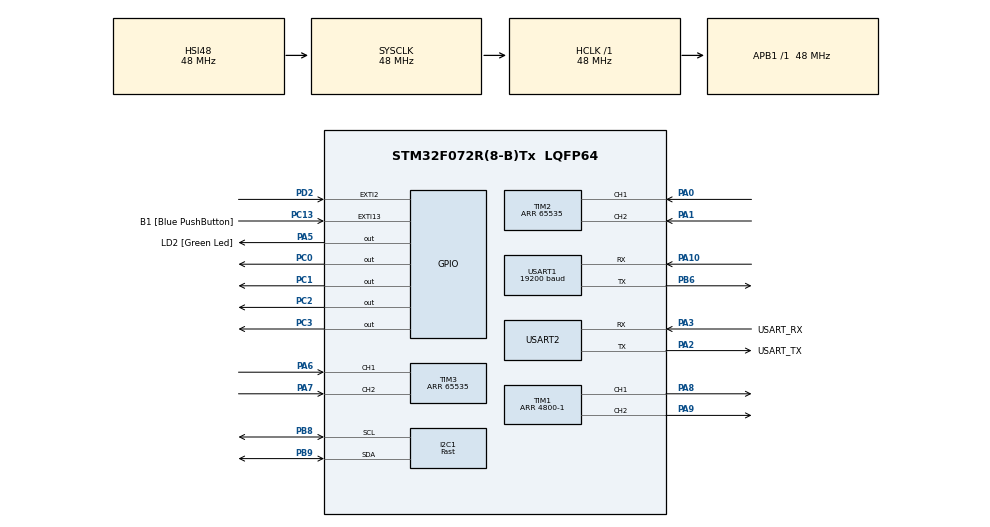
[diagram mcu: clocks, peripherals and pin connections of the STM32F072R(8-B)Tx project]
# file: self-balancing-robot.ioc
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Dma.Request0=USART1_RX
Dma.Request1=USART1_TX
Dma.USART1_RX.0.Direction=DMA_PERIPH_TO_MEMORY
Dma.USART1_RX.0.Instance=DMA1_Channel3
Dma.USART1_RX.0.MemDataAlignment=DMA_MDATAALIGN_BYTE
Dma.USART1_RX.0.MemInc=DMA_MINC_ENABLE
Dma.USART1_RX.0.Mode=DMA_CIRCULAR
Dma.USART1_RX.0.PeriphDataAlignment=DMA_PDATAALIGN_BYTE
Dma.USART1_RX.0.PeriphInc=DMA_PINC_DISABLE
Dma.USART1_RX.0.Priority=DMA_PRIORITY_LOW
Dma.USART1_TX.1.Direction=DMA_MEMORY_TO_PERIPH
Dma.USART1_TX.1.Instance=DMA1_Channel2
Dma.USART1_TX.1.MemDataAlignment=DMA_MDATAALIGN_BYTE
Dma.USART1_TX.1.MemInc=DMA_MINC_ENABLE
Dma.USART1_TX.1.Mode=DMA_NORMAL
Dma.USART1_TX.1.PeriphDataAlignment=DMA_PDATAALIGN_BYTE
Dma.USART1_TX.1.PeriphInc=DMA_PINC_DISABLE
Dma.USART1_TX.1.Priority=DMA_PRIORITY_LOW
I2C1.I2C_Speed_Mode=I2C_Fast
I2C1.Timing=0x0000020B
Mcu.Family=STM32F0
Mcu.Name=STM32F072R(8-B)Tx
Mcu.Package=LQFP64
NVIC.DMA1_Channel2_3_IRQn=true\:1\:0\:true\:false\:true\:false
NVIC.EXTI2_3_IRQn=true\:2\:0\:true\:false\:true\:true
NVIC.EXTI4_15_IRQn=true\:0\:0\:true\:true\:true\:1\:true
NVIC.USART1_IRQn=true\:1\:0\:true\:false\:true\:true
PA0.GPIO_PuPd=GPIO_PULLUP
PA0.GPIO_Speed=GPIO_SPEED_FREQ_HIGH
PA0.Signal=S_TIM2_CH1_ETR
PA1.GPIO_PuPd=GPIO_PULLUP
PA1.GPIO_Speed=GPIO_SPEED_FREQ_HIGH
PA1.Signal=S_TIM2_CH2
PA10.Mode=Asynchronous
PA10.Signal=USART1_RX
PA13.GPIO_Label=TMS
PA13.Mode=Serial_Wire
PA13.Signal=SYS_SWDIO
PA14.GPIO_Label=TCK
PA14.Mode=Serial_Wire
PA14.Signal=SYS_SWCLK
PA2.GPIO_Label=USART_TX
PA2.GPIO_Mode=GPIO_MODE_AF_PP
PA2.GPIO_PuPd=GPIO_NOPULL
PA2.GPIO_Speed=GPIO_SPEED_FREQ_HIGH
PA2.Mode=Asynchronous
PA2.Signal=USART2_TX
PA3.GPIO_Label=USART_RX
PA3.GPIO_Mode=GPIO_MODE_AF_PP
PA3.GPIO_PuPd=GPIO_NOPULL
PA3.GPIO_Speed=GPIO_SPEED_FREQ_HIGH
PA3.Mode=Asynchronous
PA3.Signal=USART2_RX
PA5.GPIO_Label=LD2 [Green Led]
PA5.GPIO_Mode=GPIO_MODE_OUTPUT_PP
PA5.GPIO_PuPd=GPIO_PULLUP
PA5.GPIO_Speed=GPIO_SPEED_FREQ_HIGH
PA5.PinState=GPIO_PIN_RESET
PA5.Signal=GPIO_Output
PA6.GPIO_PuPd=GPIO_PULLUP
PA6.GPIO_Speed=GPIO_SPEED_FREQ_HIGH
PA6.Signal=S_TIM3_CH1
PA7.GPIO_PuPd=GPIO_PULLUP
PA7.GPIO_Speed=GPIO_SPEED_FREQ_HIGH
PA7.Signal=S_TIM3_CH2
PA8.GPIO_PuPd=GPIO_PULLUP
PA8.GPIO_Speed=GPIO_SPEED_FREQ_HIGH
PA8.Signal=S_TIM1_CH1
PA9.GPIO_PuPd=GPIO_PULLUP
PA9.GPIO_Speed=GPIO_SPEED_FREQ_HIGH
PA9.Signal=S_TIM1_CH2
PB6.Mode=Asynchronous
PB6.Signal=USART1_TX
PB8.GPIO_FM8=__NULL
PB8.Mode=I2C
PB8.Signal=I2C1_SCL
PB9.Mode=I2C
PB9.Signal=I2C1_SDA
PC0.GPIO_PuPd=GPIO_PULLUP
PC0.GPIO_Speed=GPIO_SPEED_FREQ_HIGH
PC0.Signal=GPIO_Output
PC1.GPIO_PuPd=GPIO_PULLUP
PC1.GPIO_Speed=GPIO_SPEED_FREQ_HIGH
PC1.Signal=GPIO_Output
PC13.GPIO_Label=B1 [Blue PushButton]
PC13.GPIO_ModeDefaultEXTI=GPIO_MODE_IT_FALLING
PC13.GPIO_PuPd=GPIO_NOPULL
PC13.Signal=GPXTI13
PC2.GPIO_PuPd=GPIO_PULLUP
PC2.GPIO_Speed=GPIO_SPEED_FREQ_HIGH
PC2.Signal=GPIO_Output
PC3.GPIO_PuPd=GPIO_PULLUP
PC3.GPIO_Speed=GPIO_SPEED_FREQ_HIGH
PC3.Signal=GPIO_Output
PD2.GPIO_PuPd=GPIO_PULLUP
PD2.Signal=GPXTI2
ProjectManager.HeapSize=0x200
ProjectManager.StackSize=0x400
ProjectManager.TargetToolchain=MDK-ARM V5
RCC.AHBFreq_Value=48000000
RCC.APB1Freq_Value=48000000
RCC.APB1TimFreq_Value=48000000
RCC.FLatency-AdvancedSettings=FLASH_LATENCY_1
RCC.HCLKFreq_Value=48000000
RCC.PLLDivider=RCC_PREDIV_DIV2
RCC.PLLMUL=RCC_PLL_MUL14
RCC.PREFETCH_ENABLE-AdvancedSettings=1
RCC.SYSCLKFreq_VALUE=48000000
RCC.SYSCLKSource=RCC_SYSCLKSOURCE_HSI48
SH.S_TIM1_CH1.0=TIM1_CH1,PWM Generation1 CH1
SH.S_TIM1_CH2.0=TIM1_CH2,PWM Generation2 CH2
SH.S_TIM2_CH1_ETR.0=TIM2_CH1,Encoder_Interface
SH.S_TIM2_CH2.0=TIM2_CH2,Encoder_Interface
SH.S_TIM3_CH1.0=TIM3_CH1,Encoder_Interface
SH.S_TIM3_CH2.0=TIM3_CH2,Encoder_Interface
TIM1.Channel-PWM\ Generation1\ CH1=TIM_CHANNEL_1
TIM1.Channel-PWM\ Generation2\ CH2=TIM_CHANNEL_2
TIM1.Period=4800-1
TIM1.Pulse-PWM\ Generation1\ CH1=0
TIM1.Pulse-PWM\ Generation2\ CH2=0
TIM2.EncoderMode=TIM_ENCODERMODE_TI12
TIM2.IC1Filter=1
TIM2.IC2Filter=1
TIM2.Period=65535
TIM3.EncoderMode=TIM_ENCODERMODE_TI12
TIM3.IC1Filter=1
TIM3.IC2Filter=1
TIM3.Period=65535
USART1.BaudRate=19200
USART1.VirtualMode-Asynchronous=VM_ASYNC
USART1.WordLength=WORDLENGTH_8B
USART2.VirtualMode=VM_ASYNC
USART2.VirtualMode-Asynchronous=VM_ASYNC
USART2.WordLength=WORDLENGTH_8B
VP_TIM1_VS_ClockSourceINT.Mode=Internal
board=NUCLEO-F072RB

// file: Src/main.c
/**
  ******************************************************************************
  * @file           : main.c
  * @brief          : Main program body
  ******************************************************************************
  ** This notice applies to any and all portions of this file
  * that are not between comment pairs USER CODE BEGIN and
  * USER CODE END. Other portions of this file, whether
  * inserted by the user or by software development tools
  * are owned by their respective copyright owners.
  *
  * COPYRIGHT(c) 2018 STMicroelectronics
  *
  * Redistribution and use in source and binary forms, with or without modification,
  * are permitted provided that the following conditions are met:
  *   1. Redistributions of source code must retain the above copyright notice,
  *      this list of conditions and the following disclaimer.
  *   2. Redistributions in binary form must reproduce the above copyright notice,
  *      this list of conditions and the following disclaimer in the documentation
  *      and/or other materials provided with the distribution.
  *   3. Neither the name of STMicroelectronics nor the names of its contributors
  *      may be used to endorse or promote products derived from this software
  *      without specific prior written permission.
  *
  * THIS SOFTWARE IS PROVIDED BY THE COPYRIGHT HOLDERS AND CONTRIBUTORS "AS IS"
  * AND ANY EXPRESS OR IMPLIED WARRANTIES, INCLUDING, BUT NOT LIMITED TO, THE
  * IMPLIED WARRANTIES OF MERCHANTABILITY AND FITNESS FOR A PARTICULAR PURPOSE ARE
  * DISCLAIMED. IN NO EVENT SHALL THE COPYRIGHT HOLDER OR CONTRIBUTORS BE LIABLE
  * FOR ANY DIRECT, INDIRECT, INCIDENTAL, SPECIAL, EXEMPLARY, OR CONSEQUENTIAL
  * DAMAGES (INCLUDING, BUT NOT LIMITED TO, PROCUREMENT OF SUBSTITUTE GOODS OR
  * SERVICES; LOSS OF USE, DATA, OR PROFITS; OR BUSINESS INTERRUPTION) HOWEVER
  * CAUSED AND ON ANY THEORY OF LIABILITY, WHETHER IN CONTRACT, STRICT LIABILITY,
  * OR TORT (INCLUDING NEGLIGENCE OR OTHERWISE) ARISING IN ANY WAY OUT OF THE USE
  * OF THIS SOFTWARE, EVEN IF ADVISED OF THE POSSIBILITY OF SUCH DAMAGE.
  *
  ******************************************************************************
  */
#include "main.h"
#include "stm32f0xx_hal.h"
#include "dma.h"
#include "i2c.h"
#include "tim.h"
#include "usart.h"
#include "gpio.h"

/* USER CODE BEGIN PV */
/* Private variables ---------------------------------------------------------*/

/* USER CODE END PV */

void SystemClock_Config(void);
static void MX_NVIC_Init(void);

/* USER CODE BEGIN PFP */
/* Private function prototypes -----------------------------------------------*/

extern void self_balancing_robot_main_Init(void);		//初始化副程式 ，在 self-balancing-robot_main_Init.c 中

/* USER CODE END PFP */

int main(void)
{

  /* MCU Configuration----------------------------------------------------------*/

  /* Reset of all peripherals, Initializes the Flash interface and the Systick. */
  HAL_Init();

  /* Configure the system clock */
  SystemClock_Config();

  /* Initialize all configured peripherals */
  MX_GPIO_Init();
  MX_DMA_Init();
  MX_USART2_UART_Init();
  MX_I2C1_Init();
  MX_TIM1_Init();
  MX_TIM2_Init();
  MX_TIM3_Init();
  MX_USART1_UART_Init();

  /* Initialize interrupts */
  MX_NVIC_Init();
  /* USER CODE BEGIN 2 */

	self_balancing_robot_main_Init();		//初始化副程式

  /* USER CODE END 2 */

  /* Infinite loop */
  while (1)
  {

  }

}

void SystemClock_Config(void)
{

  RCC_OscInitTypeDef RCC_OscInitStruct;
  RCC_ClkInitTypeDef RCC_ClkInitStruct;
  RCC_PeriphCLKInitTypeDef PeriphClkInit;

    /**Initializes the CPU, AHB and APB busses clocks
    */
  RCC_OscInitStruct.OscillatorType = RCC_OSCILLATORTYPE_HSI|RCC_OSCILLATORTYPE_HSI48;
  RCC_OscInitStruct.HSIState = RCC_HSI_ON;
  RCC_OscInitStruct.HSI48State = RCC_HSI48_ON;
  RCC_OscInitStruct.HSICalibrationValue = 16;
  RCC_OscInitStruct.PLL.PLLState = RCC_PLL_NONE;
  if (HAL_RCC_OscConfig(&RCC_OscInitStruct) != HAL_OK)
  {
    _Error_Handler(__FILE__, __LINE__);
  }

    /**Initializes the CPU, AHB and APB busses clocks
    */
  RCC_ClkInitStruct.ClockType = RCC_CLOCKTYPE_HCLK|RCC_CLOCKTYPE_SYSCLK
                              |RCC_CLOCKTYPE_PCLK1;
  RCC_ClkInitStruct.SYSCLKSource = RCC_SYSCLKSOURCE_HSI48;
  RCC_ClkInitStruct.AHBCLKDivider = RCC_SYSCLK_DIV1;
  RCC_ClkInitStruct.APB1CLKDivider = RCC_HCLK_DIV1;

  if (HAL_RCC_ClockConfig(&RCC_ClkInitStruct, FLASH_LATENCY_1) != HAL_OK)
  {
    _Error_Handler(__FILE__, __LINE__);
  }

  PeriphClkInit.PeriphClockSelection = RCC_PERIPHCLK_USART1|RCC_PERIPHCLK_USART2
                              |RCC_PERIPHCLK_I2C1;
  PeriphClkInit.Usart1ClockSelection = RCC_USART1CLKSOURCE_PCLK1;
  PeriphClkInit.Usart2ClockSelection = RCC_USART2CLKSOURCE_PCLK1;
  PeriphClkInit.I2c1ClockSelection = RCC_I2C1CLKSOURCE_HSI;
  if (HAL_RCCEx_PeriphCLKConfig(&PeriphClkInit) != HAL_OK)
  {
    _Error_Handler(__FILE__, __LINE__);
  }

    /**Configure the Systick interrupt time
    */
  HAL_SYSTICK_Config(HAL_RCC_GetHCLKFreq()/1000);

    /**Configure the Systick
    */
  HAL_SYSTICK_CLKSourceConfig(SYSTICK_CLKSOURCE_HCLK);

  /* SysTick_IRQn interrupt configuration */
  HAL_NVIC_SetPriority(SysTick_IRQn, 0, 0);
}

/**
  * @brief NVIC Configuration.
  * @retval None
  */
static void MX_NVIC_Init(void)
{
  /* EXTI4_15_IRQn interrupt configuration */
  HAL_NVIC_SetPriority(EXTI4_15_IRQn, 0, 0);
  HAL_NVIC_EnableIRQ(EXTI4_15_IRQn);
}

void _Error_Handler(char *file, int line)
{
  while(1)
  {
  }
}

/************************ (C) COPYRIGHT STMicroelectronics *****END OF FILE****/
